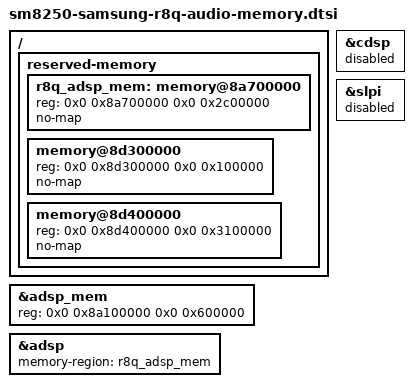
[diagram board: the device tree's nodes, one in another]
/*
 * Exact Samsung r8q ADSP reservation for the integrated audio graph.
 *
 * This is the reviewed 44 MiB stock ADSP region. It preserves the existing
 * generic reserved-memory union with a prefix and no-map guards. The v6
 * aggregator includes this file before the graph. No firmware/calibration
 * payload is encoded here.
 */

/delete-node/ &spss_mem;
/delete-node/ &cdsp_secure_heap;

&adsp_mem {
	reg = <0x0 0x8a100000 0x0 0x600000>;
};

/ {
	reserved-memory {
		r8q_adsp_mem: memory@8a700000 {
			reg = <0x0 0x8a700000 0x0 0x2c00000>;
			no-map;
		};

		memory@8d300000 {
			reg = <0x0 0x8d300000 0x0 0x100000>;
			no-map;
		};

		memory@8d400000 {
			reg = <0x0 0x8d400000 0x0 0x3100000>;
			no-map;
		};
	};
};

&adsp {
	memory-region = <&r8q_adsp_mem>;
};

&cdsp {
	status = "disabled";
};

&slpi {
	status = "disabled";
};
